# AST1080 register map
File version: 1.0
CPU: CM4 r0p1, little endian, MPU, FPU, 4 interrupt priority bits, 256 interrupts
Registers are 32-bit, read-write, reset 0x0 unless marked. A register's access mark holds for its fields unless they carry their own. Offsets are from the block's base; [hi:lo] are bit positions; {n}, {i} and the like mark numbered series.

## ehci
Base 0x74121000
Same registers: ehci1 0x74123000
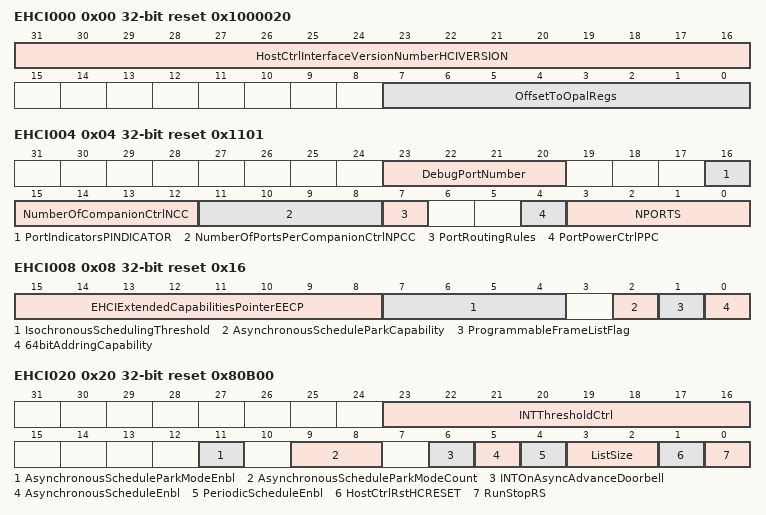
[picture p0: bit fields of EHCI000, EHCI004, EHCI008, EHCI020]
0x00 EHCI000 reset 0x1000020 — Capability Registers Length (CAPLENGTH)
  [31:16] HostCtrlInterfaceVersionNumberHCIVERSION ro — Host Controller Interface Version Number (HCIVERSION)
  [7:0] OffsetToOpalRegs ro — Offset to Operational Registers
0x04 EHCI004 reset 0x1101 — Structural Parameters (HCSPARAMS)
  [23:20] DebugPortNumber ro
  [16] PortIndicatorsPINDICATOR ro
  [15:12] NumberOfCompanionCtrlNCC ro — Number of Companion Controller (N_CC)
  [11:8] NumberOfPortsPerCompanionCtrlNPCC ro — Number of Ports per Companion Controller (N_PCC)
  [7] PortRoutingRules ro
    0=_The_First_NPCC_Ports_Are_Routed_To_The_Lowest_Numbered_Function; 1=_The_Port_Routing_Is_Explicitly_Enumerated_By_The_First_NPORTS_Elements
  [4] PortPowerCtrlPPC ro — Port Power Control (PPC)
  [3:0] NPORTS ro
0x08 EHCI008 reset 0x16 — Capability Parameters (HCCPARAMS)
  [15:8] EHCIExtendedCapabilitiesPointerEECP ro
  [7:4] IsochronousSchedulingThreshold ro
  [2] AsynchronousScheduleParkCapability ro
  [1] ProgrammableFrameListFlag ro
  [0] 64bitAddringCapability ro — 64-bit Addressing Capability
    0=Data_Structures_Using_32bit_Address_Memory_Pointers; 1=Data_Structures_Using_64bit_Address_Memory_Pointers
{0xC+4i} EHCIC[{i}] (i=0..4) reset not defined — Companion Port Route Description (HCSP-PORTROUTE)
0x20 EHCI020 reset 0x80B00 — USB Command Register (USBCMD)
  [23:16] INTThresholdCtrl — Interrupt Threshold Control
  [11] AsynchronousScheduleParkModeEnbl — Asynchronous Schedule Park Mode Enable
  [9:8] AsynchronousScheduleParkModeCount
  [6] INTOnAsyncAdvanceDoorbell — Interrupt on Async Advance Doorbell
  [5] AsynchronousScheduleEnbl — Asynchronous Schedule Enable
    0=Do_Not_Process_The_Asynchronous_Schedule; 1=Use_The_ASYNCLISTADDR_Register_To_Access_The_Asynchronous_Schedule
  [4] PeriodicScheduleEnbl — Periodic Schedule Enable
    0=Do_Not_Process_The_Periodic_Schedule; 1=Use_The_PERIODICLISTBASE_Register_To_Access_The_Periodic_Schedule
  [3:2] ListSize
    0=1024_Elements_4096_Bytes_Default_Value; 1=512_Elements_2048_Bytes; 2=256_Elements_1024_Bytes__For_Resourceconstrained_Environments
  [1] HostCtrlRstHCRESET — Host Controller Reset (HCRESET)
  [0] RunStopRS
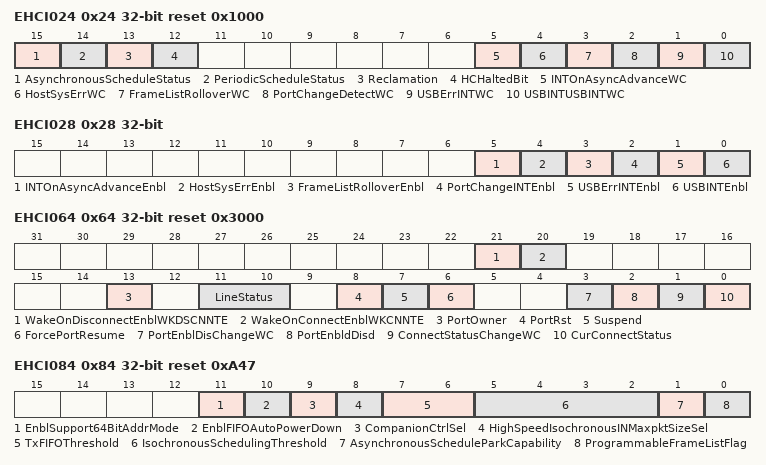
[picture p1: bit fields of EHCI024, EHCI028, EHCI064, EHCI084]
0x24 EHCI024 reset 0x1000 — USB Status Register (USBSTS)
  [15] AsynchronousScheduleStatus ro
  [14] PeriodicScheduleStatus ro
  [13] Reclamation ro
  [12] HCHaltedBit ro
  [5] INTOnAsyncAdvanceWC — Interrupt on Async Advance (WC)
  [4] HostSysErrWC — Host System Error (WC)
  [3] FrameListRolloverWC
  [2] PortChangeDetectWC
  [1] USBErrINTWC — USB Error Interrupt (WC)
  [0] USBINTUSBINTWC — USB Interrupt (USBINT) (WC)
0x28 EHCI028 — USB Interrupt Enable Register (USBINTR)
  [5] INTOnAsyncAdvanceEnbl — Interrupt on Async Advance Enable
  [4] HostSysErrEnbl — Host System Error Enable
  [3] FrameListRolloverEnbl — Frame List Rollover Enable
  [2] PortChangeINTEnbl — Port Change Interrupt Enable
  [1] USBErrINTEnbl — USB Error Interrupt Enable
  [0] USBINTEnbl — USB Interrupt Enable
0x2C EHCI02C — Frame Index Register (FRINDEX)
  [13:0] FrameIndex
0x30 EHCI030 — Control Data Structure Segment Register (CTRLDSSEGMENT)
  [1:0] BaseAddrHi — Base Address Hi
0x34 EHCI034 — Periodic Frame List Base Address Register (PERIODICLISTBASE)
  [31:12] BaseAddr — Base Address
0x38 EHCI038 — Current Asynchronous List Address Register (ASYNCLISTADDR)
  [31:5] LinkPointerLowLPL
0x60 EHCI060 — Configure Flag Register (CONFIGFLAG)
  [0] ConfigureFlagCF
    0=_Port_Routing_Control_Logic_Defaultroutes_Each_Port_To_An_Implementation; 1=_Port_Routing_Control_Logic_Defaultroutes_All_Ports_To_This_Host_Controller
0x64 EHCI064 reset 0x3000 — Port1 Status/Control Register (PORTSC1)
  [21] WakeOnDisconnectEnblWKDSCNNTE — Wake on Disconnect Enable (WKDSCNNT_E)
  [20] WakeOnConnectEnblWKCNNTE — Wake on Connect Enable (WKCNNT_E)
  [13] PortOwner
  [11:10] LineStatus ro
    3=10__USB_State__Interpretation______________________________
  [8] PortRst — Port Reset
    0=Port_Is_Not_In_Reset; 1=Port_Is_In_Reset
  [7] Suspend
    0=Port_Not_In_Suspend_State; 1=Port_In_Suspend_State
  [6] ForcePortResume
    0=No_Resume_Kstate_Detecteddriven_On_Port; 1=Resume_Detecteddriven_On_Port
  [3] PortEnblDisChangeWC — Port Enable/Disable Change (WC)
    0=No_Change; 1=Port_Enableddisabled_Status_Has_Changed
  [2] PortEnbldDisd — Port Enabled/Disabled
    0=Disable; 1=Enable
  [1] ConnectStatusChangeWC
    0=No_Change; 1=Change_In_Current_Connect_Status
  [0] CurConnectStatus ro — Current Connect Status
    0=No_Device_Is_Present; 1=Device_Is_Present_On_Port
0x80 EHCI080 reset 0x20 — Frame Length Adjustment Register (FLADJ)
  [5:0] FrameLengthTimingValue
0x84 EHCI084 reset 0xA47 — Controller Fine-tune Register
  [11] EnblSupport64BitAddrMode — Enable support 64 bit address mode
  [10] EnblFIFOAutoPowerDown — Enable FIFO auto power down
    0=Disable_Default; 1=Enable
  [9] CompanionCtrlSel — Companion Controller Selection
    0=No_Companion_Controller_Reported; 1=One_Companion_Controller_Reported
  [8] HighSpeedIsochronousINMaxpktSizeSel — High speed Isochronous IN MaxPacketSize selection
    0=MaxPacketSize_Is_Determined_By_TransactionXLength_Or_Maximum_Packet_Size_Whichever_Is_Less; 1=MaxPacketSize_Is_Determined_By_Maximum_Packet_Size_Field
  [7:6] TxFIFOThreshold — Transmit FIFO Threshold
    0=128_Bytes; 1=256_Bytes; 2=512_Bytes; 3=768_Bytes
  [5:2] IsochronousSchedulingThreshold
  [1] AsynchronousScheduleParkCapability
  [0] ProgrammableFrameListFlag
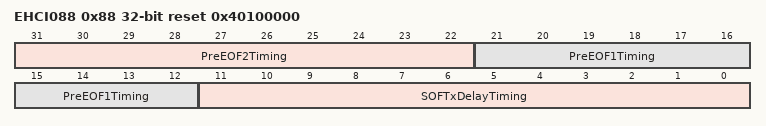
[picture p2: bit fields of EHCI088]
0x88 EHCI088 reset 0x40100000 — Frame Timing Adjustment
  [31:22] PreEOF2Timing
  [21:12] PreEOF1Timing
  [11:0] SOFTxDelayTiming — SOF transmit delay timing
0x8C EHCI08C reset 0x2 — Hardware Revision Number Register
  [7:0] HwRevNumber ro — Hardware revision number
